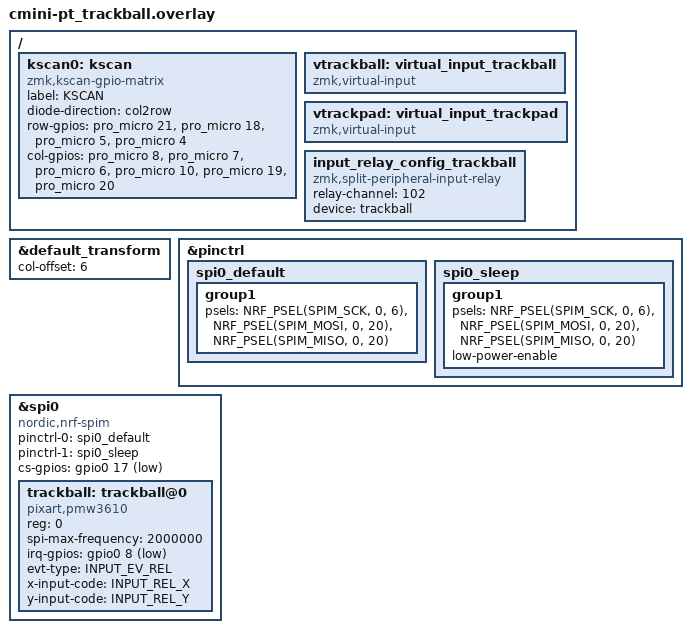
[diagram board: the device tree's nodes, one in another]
#include "cmini-pt.dtsi"
#define INPUT_EV_KEY 0x01               /**< Key event */
#define INPUT_EV_REL 0x02               /**< Relative coordinate event */
#define INPUT_EV_ABS 0x03               /**< Absolute coordinate event */
#define INPUT_EV_MSC 0x04               /**< Miscellaneous event */
#define INPUT_EV_VENDOR_START 0xf0      /**< Vendor specific event start */
#define INPUT_EV_VENDOR_STOP 0xff       /**< Vendor specific event stop */

#define INPUT_REL_X 0x00                /**< Relative X coordinate */
#define INPUT_REL_Y 0x01                /**< Relative Y coordinate */
#define INPUT_REL_WHEEL 0x08            /**< Relative wheel coordinate */
#define INPUT_REL_HWHEEL 0x06           /**< Relative horizontal wheel coordinate */
#define INPUT_REL_MISC 0x09             /**< Relative misc coordinate */

&default_transform {
    col-offset = <6>;
};

/ {
    kscan0: kscan {
        compatible = "zmk,kscan-gpio-matrix";
        label = "KSCAN";
        diode-direction = "col2row";

        row-gpios
        = <&pro_micro 21 (GPIO_ACTIVE_HIGH | GPIO_PULL_DOWN)>
        , <&pro_micro 18 (GPIO_ACTIVE_HIGH | GPIO_PULL_DOWN)>
        , <&pro_micro 5 (GPIO_ACTIVE_HIGH | GPIO_PULL_DOWN)>
        , <&pro_micro 4 (GPIO_ACTIVE_HIGH | GPIO_PULL_DOWN)>
        ;
    col-gpios
        = <&pro_micro 8 GPIO_ACTIVE_HIGH>
        , <&pro_micro 7 GPIO_ACTIVE_HIGH>
        , <&pro_micro 6 GPIO_ACTIVE_HIGH>
        , <&pro_micro 10 GPIO_ACTIVE_HIGH>
        , <&pro_micro 19 GPIO_ACTIVE_HIGH>
        , <&pro_micro 20 GPIO_ACTIVE_HIGH>
        ;
    };
};

&pinctrl {
    spi0_default: spi0_default {
        group1 {
            psels = <NRF_PSEL(SPIM_SCK, 0, 6)>,
                <NRF_PSEL(SPIM_MOSI, 0, 20)>,
                <NRF_PSEL(SPIM_MISO, 0, 20)>;
        };
    };

    spi0_sleep: spi0_sleep {
        group1 {
            psels = <NRF_PSEL(SPIM_SCK, 0, 6)>,
                <NRF_PSEL(SPIM_MOSI, 0, 20)>,
                <NRF_PSEL(SPIM_MISO, 0, 20)>;
            low-power-enable;
        };
    };
};

&spi0 {
    status = "okay";
    compatible = "nordic,nrf-spim";
    pinctrl-0 = <&spi0_default>;
    pinctrl-1 = <&spi0_sleep>;
    pinctrl-names = "default", "sleep";
    cs-gpios = <&gpio0 17 GPIO_ACTIVE_LOW>;

    trackball: trackball@0 {
        status = "okay";
        compatible = "pixart,pmw3610";
        reg = <0>;
        spi-max-frequency = <2000000>;
        irq-gpios = <&gpio0 8 (GPIO_ACTIVE_LOW | GPIO_PULL_UP)>;
        evt-type = <INPUT_EV_REL>;
        x-input-code = <INPUT_REL_X>;
        y-input-code = <INPUT_REL_Y>;

        /*   optional features   */
        // snipe-layers = <1>;
        // scroll-layers = <2 3>;
        // automouse-layer = <4>;
    };
};

/ {
  vtrackball: virtual_input_trackball {
      compatible = "zmk,virtual-input";
  };

  vtrackpad: virtual_input_trackpad {
    compatible = "zmk,virtual-input";
  };
};

/ {
    input_relay_config_trackball {
        compatible = "zmk,split-peripheral-input-relay";
        
        /* channel id, used to filter incoming annotated input event from split peripheral */
        /* NOTE: should matching relay-channel on peripheral overlay */
        relay-channel = <102>;

        /* virtual input device on central, which used to emit input event as an agent device */
        device = <&trackball>;
    };
};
